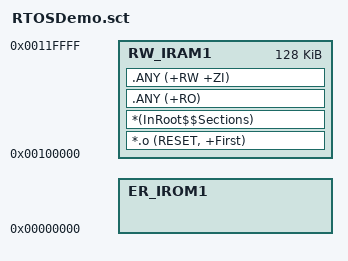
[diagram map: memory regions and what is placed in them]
; *************************************************************
; *** Scatter-Loading Description File generated by uVision ***
; *************************************************************


LR_IROM1 0x00100000 0x00020000  {    ; load region size_region
  ER_IROM1 0x00000000 0x00000000  {  ; load address = execution address
  }
  RW_IRAM1 0x00100000 0x00020000 {  ; RW data
   *.o (RESET, +First)
   *(InRoot$$Sections)
   .ANY (+RO)
   .ANY (+RW +ZI)
  }
}


;LR_IROM1 0x00100000 0x00018000  {    ; load region size_region
;  ER_IROM1 0x00100000 0x00018000  {  ; load address = execution address
;   *.o (RESET, +First)
;   *(InRoot$$Sections)
;   .ANY (+RO)
;  }
;  RW_IRAM1 0x00118000 0x00008000  {  ; RW data
;   .ANY (+RW +ZI)
;  }
;}

